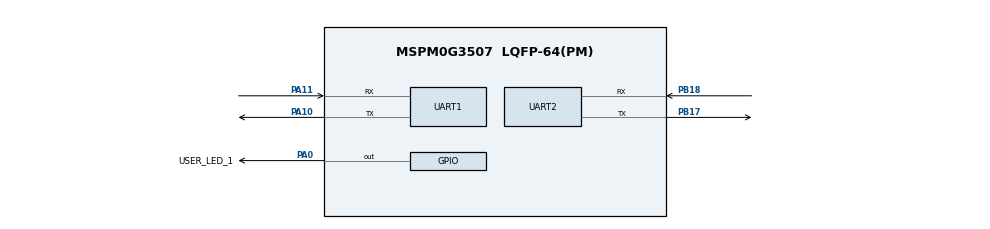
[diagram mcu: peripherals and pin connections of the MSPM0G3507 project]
/**
 * These arguments were used when this file was generated. They will be automatically applied on subsequent loads
 * via the GUI or CLI. Run CLI with '--help' for additional information on how to override these arguments.
 * @cliArgs --device "MSPM0G350X" --part "Default" --package "LQFP-64(PM)" --product "mspm0_sdk@2.05.01.00"
 * @v2CliArgs --device "MSPM0G3507" --package "LQFP-64(PM)" --product "mspm0_sdk@2.05.01.00"
 * @versions {"tool":"1.24.0+4110"}
 */

/**
 * Import the modules used in this configuration.
 */
const GPIO  = scripting.addModule("/ti/driverlib/GPIO", {}, false);
const GPIO1 = GPIO.addInstance();
const UART  = scripting.addModule("/ti/driverlib/UART", {}, false);
const UART1 = UART.addInstance();
const UART2 = UART.addInstance();

/**
 * Write custom configuration values to the imported modules.
 */
GPIO1.$name                          = "GPIO_LEDS";
GPIO1.associatedPins.create(2);
GPIO1.associatedPins[0].$name        = "USER_LED_1";
GPIO1.associatedPins[0].assignedPort = "PORTA";
GPIO1.associatedPins[0].initialValue = "SET";
GPIO1.associatedPins[0].assignedPin  = "0";
GPIO1.associatedPins[0].pin.$assign  = "PA0";
GPIO1.associatedPins[1].$name        = "USER_TEST";
GPIO1.associatedPins[1].assignedPort = "PORTA";
GPIO1.associatedPins[1].assignedPin  = "15";
GPIO1.associatedPins[1].initialValue = "SET";

const Board           = scripting.addModule("/ti/driverlib/Board", {}, false);
Board.configureUnused = true;

const SYSCTL                 = scripting.addModule("/ti/driverlib/SYSCTL", {}, false);
SYSCTL.powerPolicy           = "STANDBY0";
SYSCTL.forceDefaultClkConfig = true;
SYSCTL.clockTreeEn           = true;

UART1.$name                    = "UART_0";
UART1.rxFifoThreshold          = "DL_UART_RX_FIFO_LEVEL_ONE_ENTRY";
UART1.enableDMARX              = false;
UART1.enableDMATX              = false;
UART1.enableInternalLoopback   = false;
UART1.enabledInterrupts        = ["RX"];
UART1.enableFIFO               = false;
UART1.targetBaudRate           = 115200;
UART1.peripheral.$assign       = "UART0";
UART1.peripheral.rxPin.$assign = "PA11";
UART1.peripheral.txPin.$assign = "PA10";
UART1.txPinConfig.$name        = "ti_driverlib_gpio_GPIOPinGeneric0";
UART1.rxPinConfig.$name        = "ti_driverlib_gpio_GPIOPinGeneric1";

UART2.$name                            = "UART_2";
UART2.targetBaudRate                   = 115200;
UART2.enabledInterrupts                = ["RX"];
UART2.peripheral.$assign               = "UART2";
UART2.peripheral.rxPin.$assign         = "PB18";
UART2.peripheral.txPin.$assign         = "PB17";
UART2.txPinConfig.$name                = "ti_driverlib_gpio_GPIOPinGeneric2";
UART2.txPinConfig.direction            = scripting.forceWrite("OUTPUT");
UART2.txPinConfig.hideOutputInversion  = scripting.forceWrite(false);
UART2.txPinConfig.onlyInternalResistor = scripting.forceWrite(false);
UART2.txPinConfig.passedPeripheralType = scripting.forceWrite("Digital");
UART2.rxPinConfig.$name                = "ti_driverlib_gpio_GPIOPinGeneric3";
UART2.rxPinConfig.hideOutputInversion  = scripting.forceWrite(false);
UART2.rxPinConfig.onlyInternalResistor = scripting.forceWrite(false);
UART2.rxPinConfig.passedPeripheralType = scripting.forceWrite("Digital");

/**
 * Pinmux solution for unlocked pins/peripherals. This ensures that minor changes to the automatic solver in a future
 * version of the tool will not impact the pinmux you originally saw.  These lines can be completely deleted in order to
 * re-solve from scratch.
 */
GPIO1.associatedPins[1].pin.$suggestSolution = "PA15";
Board.peripheral.$suggestSolution            = "DEBUGSS";
Board.peripheral.swclkPin.$suggestSolution   = "PA20";
Board.peripheral.swdioPin.$suggestSolution   = "PA19";
